# ESP32-P4-LP register map
Vendor: ESPRESSIF SYSTEMS (SHANGHAI) CO., LTD.; Series: ESP32 P-Series; File version: 3
CPU: RV32IMAC r0p0, little endian, no MPU, no FPU, 0 interrupt priority bits
Address unit: 32 bits
Registers are 32-bit, read-write, reset 0x0 unless marked. A register's access mark holds for its fields unless they carry their own. Offsets are from the block's base; [hi:lo] are bit positions; {n}, {i} and the like mark numbered series.

## LP_TRNG
Base 0x50126000
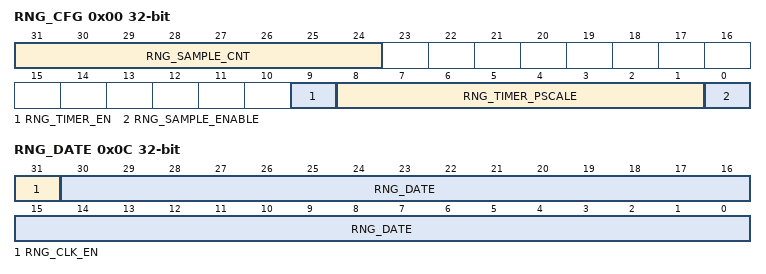
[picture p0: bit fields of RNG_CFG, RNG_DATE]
0x00 RNG_CFG access per field — configure rng register
  [31:24] RNG_SAMPLE_CNT ro — get rng RO sample cnt
  [9] RNG_TIMER_EN rw — enable rng xor async rng timer
  [8:1] RNG_TIMER_PSCALE rw — configure rng timer clk div
  [0] RNG_SAMPLE_ENABLE rw — enable rng RO 1: enable RO 0: disable RO
0x04 RNG_DATA ro — RNG result register
  [31:0] RNG_DATA — get rng data
0x08 RNG_RSTN
  [0] RNG_RSTN — enable rng system reset: 1: not reset, 0: reset
0x0C RNG_DATE
  [31] RNG_CLK_EN, [30:0] RNG_DATE

## LP_TSENS — Low-power Temperature Sensor
Base 0x5012F000
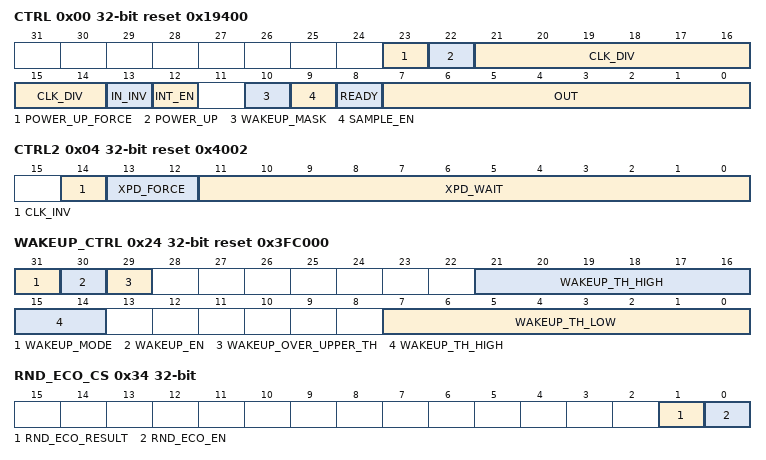
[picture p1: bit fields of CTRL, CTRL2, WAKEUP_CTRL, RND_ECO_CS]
0x00 CTRL access per field reset 0x19400 — Tsens configuration.
  [23] POWER_UP_FORCE rw — 1: dump out & power up controlled by SW, 0: by FSM.
  [22] POWER_UP rw — Temperature sensor power up.
  [21:14] CLK_DIV rw — Temperature sensor clock divider.
  [13] IN_INV rw — Invert temperature sensor data.
  [12] INT_EN rw — Enable temperature sensor to send out interrupt.
  [10] WAKEUP_MASK rw — Wake up signal mask.
  [9] SAMPLE_EN rw — Enable sample signal for wakeup module.
  [8] READY ro — Indicate temperature sensor out ready.
  [7:0] OUT ro — Temperature sensor data out.
0x04 CTRL2 reset 0x4002 — Tsens configuration.
  [14] CLK_INV, [13:12] XPD_FORCE, [11:0] XPD_WAIT
0x08 INT_RAW — Tsens interrupt raw registers.
  [0] COCPU_TSENS_WAKE_INT_RAW — Tsens wakeup interrupt raw.
0x0C INT_ST ro — Tsens interrupt status registers.
  [0] COCPU_TSENS_WAKE_INT_ST — Tsens wakeup interrupt status.
0x10 INT_ENA — Tsens interrupt enable registers.
  [0] COCPU_TSENS_WAKE_INT_ENA — Tsens wakeup interrupt enable.
0x14 INT_CLR wo — Tsens interrupt clear registers.
  [0] COCPU_TSENS_WAKE_INT_CLR — Tsens wakeup interrupt clear.
0x18 CLK_CONF — Tsens regbank configuration registers.
  [0] CLK_EN — Tsens regbank clock gating enable.
0x1C INT_ENA_W1TS wo — Tsens wakeup interrupt enable assert.
  [0] COCPU_TSENS_WAKE_INT_ENA_W1TS — Write 1 to this field to assert interrupt enable.
0x20 INT_ENA_W1TC wo — Tsens wakeup interrupt enable deassert.
  [0] COCPU_TSENS_WAKE_INT_ENA_W1TC — Write 1 to this field to deassert interrupt enable.
0x24 WAKEUP_CTRL access per field reset 0x3FC000 — Tsens wakeup control registers.
  [31] WAKEUP_MODE rw — 0:absolute value comparison mode. 1: relative value comparison mode.
  [30] WAKEUP_EN rw — Tsens wakeup enable.
  [29] WAKEUP_OVER_UPPER_TH ro — Indicates that this wakeup event arose from exceeding upper threshold.
  [21:14] WAKEUP_TH_HIGH rw — Upper threshold.
  [7:0] WAKEUP_TH_LOW rw — Lower threshold.
0x28 SAMPLE_RATE reset 0x14 — Hardware automatic sampling control registers.
  [15:0] SAMPLE_RATE — Hardware automatic sampling rate.
0x2C RND_ECO_LOW
0x30 RND_ECO_HIGH reset 0xFFFFFFFF
0x34 RND_ECO_CS access per field
  [1] RND_ECO_RESULT ro, [0] RND_ECO_EN rw

## LP_WDT — Low-power Watchdog Timer
Base 0x50116000
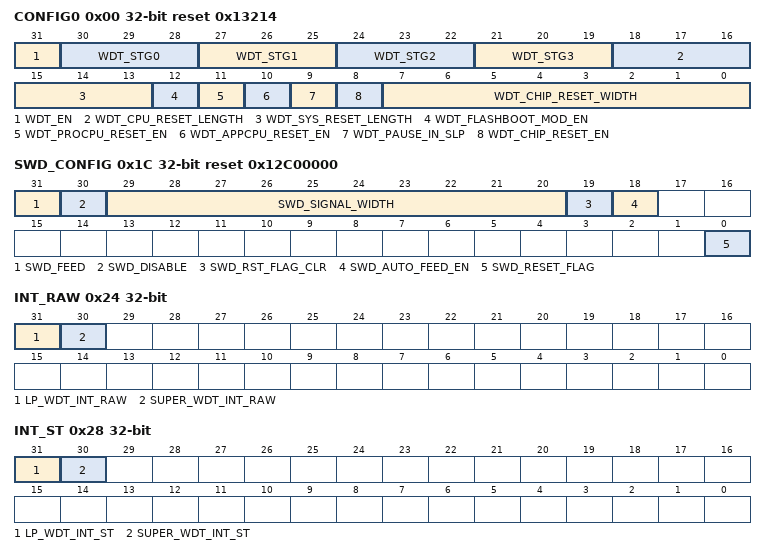
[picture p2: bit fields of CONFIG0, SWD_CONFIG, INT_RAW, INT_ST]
0x00 CONFIG0 reset 0x13214 — need_des
  [31] WDT_EN — need_des
  [30-3n:28-3n] WDT_STG{n} (n=0..3) — need_des
  [18:16] WDT_CPU_RESET_LENGTH — need_des
  [15:13] WDT_SYS_RESET_LENGTH — need_des
  [12] WDT_FLASHBOOT_MOD_EN — need_des
  [11] WDT_PROCPU_RESET_EN — need_des
  [10] WDT_APPCPU_RESET_EN — need_des
  [9] WDT_PAUSE_IN_SLP — need_des
  [8] WDT_CHIP_RESET_EN — need_des
  [7:0] WDT_CHIP_RESET_WIDTH — need_des
0x04 CONFIG1 reset 0x30D40 — need_des
  [31:0] WDT_STG0_HOLD
0x08 CONFIG2 reset 0x13880 — need_des
  [31:0] WDT_STG1_HOLD
0x0C CONFIG3 reset 0xFFF — need_des
  [31:0] WDT_STG2_HOLD
0x10 CONFIG4 reset 0xFFF — need_des
  [31:0] WDT_STG3_HOLD
0x14 FEED wo — need_des
  [31] FEED
0x18 WPROTECT — need_des
  [31:0] WDT_WKEY
0x1C SWD_CONFIG access per field reset 0x12C00000 — need_des
  [31] SWD_FEED wo — need_des
  [30] SWD_DISABLE rw — need_des
  [29:20] SWD_SIGNAL_WIDTH rw — need_des
  [19] SWD_RST_FLAG_CLR wo — need_des
  [18] SWD_AUTO_FEED_EN rw — need_des
  [0] SWD_RESET_FLAG ro — need_des
0x20 SWD_WPROTECT — need_des
  [31:0] SWD_WKEY
0x24 INT_RAW — need_des
  [31] LP_WDT_INT_RAW — need_des
  [30] SUPER_WDT_INT_RAW — need_des
0x28 INT_ST ro — need_des
  [31] LP_WDT_INT_ST — need_des
  [30] SUPER_WDT_INT_ST — need_des
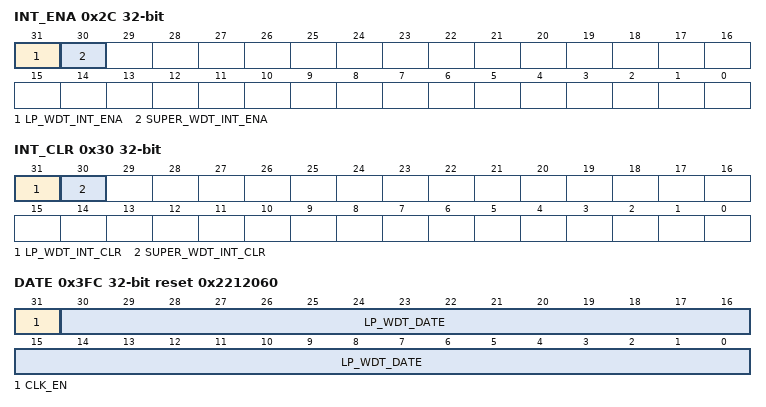
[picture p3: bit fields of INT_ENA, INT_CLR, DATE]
0x2C INT_ENA — need_des
  [31] LP_WDT_INT_ENA — need_des
  [30] SUPER_WDT_INT_ENA — need_des
0x30 INT_CLR wo — need_des
  [31] LP_WDT_INT_CLR — need_des
  [30] SUPER_WDT_INT_CLR — need_des
0x3FC DATE reset 0x2212060 — need_des
  [31] CLK_EN — need_des
  [30:0] LP_WDT_DATE — need_des

## PAU — PAU Peripheral
Base 0x60093000
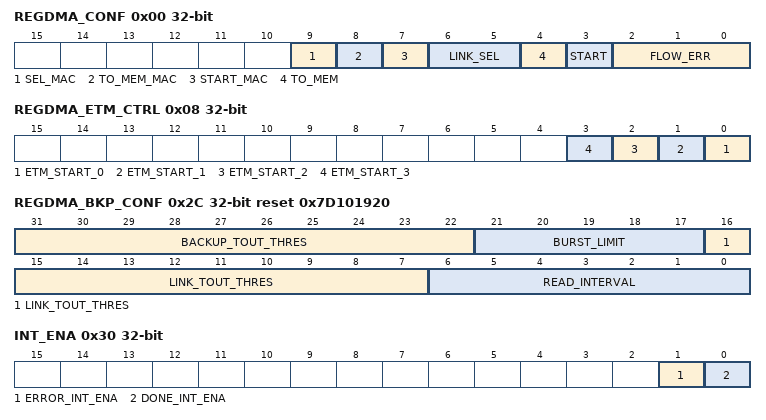
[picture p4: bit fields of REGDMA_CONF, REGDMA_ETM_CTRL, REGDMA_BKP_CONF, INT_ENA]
0x00 REGDMA_CONF access per field — Peri backup control register
  [9] SEL_MAC rw — mac hw/sw select
  [8] TO_MEM_MAC rw — mac sw backup direction(reg to mem / mem to reg)
  [7] START_MAC wo — mac sw backup start signal
  [6:5] LINK_SEL rw — Link select
  [4] TO_MEM rw — backup direction(reg to mem / mem to reg)
  [3] START wo — backup start signal
  [2:0] FLOW_ERR ro — backup error type
0x04 REGDMA_CLK_CONF — Clock control register
  [0] CLK_EN — clock enable
0x08 REGDMA_ETM_CTRL wo — ETM start ctrl reg
  [n] ETM_START_{n} (n=0..3) — etm_start_{n} reg
0x0C REGDMA_LINK_0_ADDR — link_0_addr
  [31:0] LINK_ADDR_0 — link_0_addr reg
{0xC+4i} REGDMA_LINK_{i}_ADDR (i=1..3) — Link_{i}_addr
  [31:0] LINK_ADDR_{i} — Link_{i}_addr reg
0x1C REGDMA_LINK_MAC_ADDR — Link_mac_addr
  [31:0] LINK_ADDR_MAC — Link_mac_addr reg
0x20 REGDMA_CURRENT_LINK_ADDR ro — current link addr
  [31:0] CURRENT_LINK_ADDR — current link addr reg
0x24 REGDMA_BACKUP_ADDR ro — Backup addr
  [31:0] BACKUP_ADDR — backup addr reg
0x28 REGDMA_MEM_ADDR ro — mem addr
  [31:0] MEM_ADDR — mem addr reg
0x2C REGDMA_BKP_CONF reset 0x7D101920 — backup config
  [31:22] BACKUP_TOUT_THRES — Backup timeout threshold
  [21:17] BURST_LIMIT
  [16:7] LINK_TOUT_THRES — link wait timeout threshold
  [6:0] READ_INTERVAL — Link read_interval
0x30 INT_ENA — Read only register for error and done
  [1] ERROR_INT_ENA — error flag
  [0] DONE_INT_ENA — backup done flag
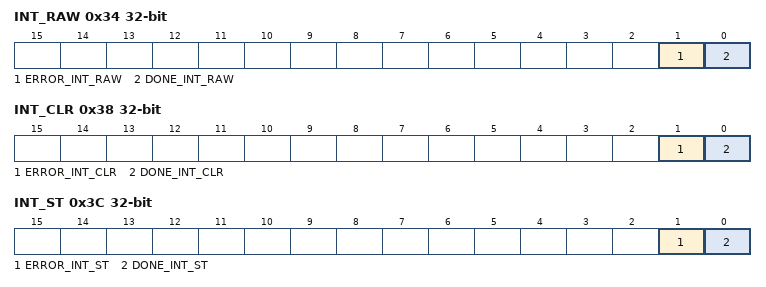
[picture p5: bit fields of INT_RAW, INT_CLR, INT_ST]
0x34 INT_RAW — Read only register for error and done
  [1] ERROR_INT_RAW — error flag
  [0] DONE_INT_RAW — backup done flag
0x38 INT_CLR wo — Read only register for error and done
  [1] ERROR_INT_CLR — error flag
  [0] DONE_INT_CLR — backup done flag
0x3C INT_ST ro — Read only register for error and done
  [1] ERROR_INT_ST — error flag
  [0] DONE_INT_ST — backup done flag
0x3FC DATE reset 0x2301310
  [27:0] DATE — REGDMA date information/ REGDMA version information.
